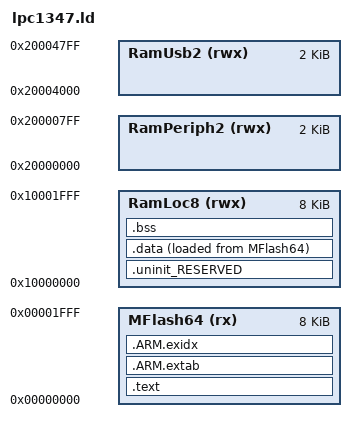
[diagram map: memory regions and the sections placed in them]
/*
 * GENERATED FILE - DO NOT EDIT
 * (C) Code Red Technologies Ltd, 2008-2012
 * Generated linker script file for LPC1347
 * Created from generic_c.ld (vLPCXpresso v4.2 (4 [Build 267] [2012-07-11] ))
 * By LPCXpresso v4.2.4 [Build 267] [2012-07-11]  on Thu Sep 13 17:44:51 CEST 2012
 */


MEMORY
{
  /* Define each memory region */
  MFlash64 (rx) : ORIGIN = 0x0, LENGTH = 0x2000 /* 8k */
  /**** NOTE: MFlash64 (64k) restricted to 8k by license type ****/ 
  RamLoc8 (rwx) : ORIGIN = 0x10000000, LENGTH = 0x2000 /* 8k */
  RamUsb2 (rwx) : ORIGIN = 0x20004000, LENGTH = 0x800 /* 2k */
  RamPeriph2 (rwx) : ORIGIN = 0x20000000, LENGTH = 0x800 /* 2k */

}
  /* Define a symbol for the top of each memory region */
  __top_MFlash64 = 0x0 + 0x10000;
  __top_RamLoc8 = 0x10000000 + 0x2000;
  __top_RamUsb2 = 0x20004000 + 0x800;
  __top_RamPeriph2 = 0x20000000 + 0x800;


ENTRY(ResetISR)

SECTIONS
{
	/* Multiple text regions not supported with this license */

	/* MAIN TEXT SECTION */	
	.text : ALIGN(4)
	{
		FILL(0xff)
		KEEP(*(.isr_vector))
		
		/* Global Section Table */
		. = ALIGN(4) ;
		__section_table_start = .;
		__data_section_table = .;
		LONG(LOADADDR(.data));
		LONG(    ADDR(.data)) ;
		LONG(  SIZEOF(.data));
		__data_section_table_end = .;
		__bss_section_table = .;
		LONG(    ADDR(.bss));
		LONG(  SIZEOF(.bss));
		__bss_section_table_end = .;
		__section_table_end = . ;
		/* End of Global Section Table */
		

		*(.after_vectors*)
		
		/* CRP data not supported with this license */
		*(.text*)
		*(.rodata .rodata.*)
		. = ALIGN(4);
		
	} > MFlash64

	/*
	 * for exception handling/unwind - some Newlib functions (in common
	 * with C++ and STDC++) use this. 
	 * Use KEEP so not discarded with --gc-sections
	 */
	.ARM.extab : ALIGN(4)
	{
		KEEP(*(.ARM.extab* .gnu.linkonce.armextab.*))
	} > MFlash64
	__exidx_start = .;
	
	.ARM.exidx : ALIGN(4)
	{
		KEEP(*(.ARM.exidx* .gnu.linkonce.armexidx.*))
	} > MFlash64
	__exidx_end = .;
	
	_etext = .;
		
	/* Multiple data regions not supported with this license */
	
	/* MAIN DATA SECTION */

	.uninit_RESERVED : ALIGN(4)
	{
		KEEP(*(.bss.$RESERVED*))
	} > RamLoc8

	.data : ALIGN(4)
	{
		FILL(0xff)
		_data = .;
		*(vtable)
		*(.data*)
		. = ALIGN(4) ;
		_edata = .;
	} > RamLoc8 AT>MFlash64

	/* Multiple bss regions not supported with this license */

	/* MAIN BSS SECTION */
	.bss : ALIGN(4)
	{
		_bss = .;
		*(.bss*)
		*(COMMON)
		. = ALIGN(4) ;
		_ebss = .;
		PROVIDE(end = .);
	} > RamLoc8
	
	PROVIDE(_pvHeapStart = .);
	PROVIDE(_vStackTop = __top_RamLoc8 - 0);
}
